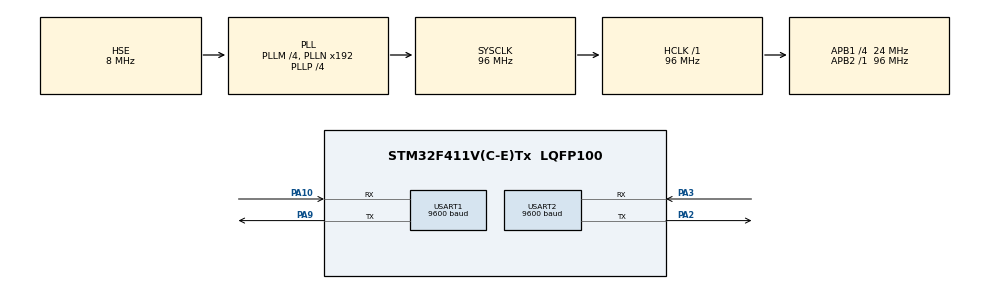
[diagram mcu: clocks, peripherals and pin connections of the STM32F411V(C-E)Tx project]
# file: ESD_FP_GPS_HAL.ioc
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Mcu.Family=STM32F4
Mcu.Name=STM32F411V(C-E)Tx
Mcu.Package=LQFP100
NVIC.PriorityGroup=NVIC_PRIORITYGROUP_0
NVIC.USART1_IRQn=true\:0\:0\:false\:false\:true\:true\:true\:true
PA10.Mode=Asynchronous
PA10.Signal=USART1_RX
PA13.Mode=Serial_Wire
PA13.Signal=SYS_JTMS-SWDIO
PA14.Mode=Serial_Wire
PA14.Signal=SYS_JTCK-SWCLK
PA2.Mode=Asynchronous
PA2.Signal=USART2_TX
PA3.Mode=Asynchronous
PA3.Signal=USART2_RX
PA9.Mode=Asynchronous
PA9.Signal=USART1_TX
PC14-OSC32_IN.Mode=LSE-External-Oscillator
PC14-OSC32_IN.Signal=RCC_OSC32_IN
PC15-OSC32_OUT.Mode=LSE-External-Oscillator
PC15-OSC32_OUT.Signal=RCC_OSC32_OUT
PH0\ -\ OSC_IN.Mode=HSE-External-Oscillator
PH0\ -\ OSC_IN.Signal=RCC_OSC_IN
PH1\ -\ OSC_OUT.Mode=HSE-External-Oscillator
PH1\ -\ OSC_OUT.Signal=RCC_OSC_OUT
ProjectManager.HeapSize=0x200
ProjectManager.StackSize=0x400
ProjectManager.TargetToolchain=STM32CubeIDE
RCC.48MHZClocksFreq_Value=48000000
RCC.AHBFreq_Value=96000000
RCC.APB1CLKDivider=RCC_HCLK_DIV4
RCC.APB1Freq_Value=24000000
RCC.APB1TimFreq_Value=48000000
RCC.APB2Freq_Value=96000000
RCC.APB2TimFreq_Value=96000000
RCC.CortexFreq_Value=96000000
RCC.HCLKFreq_Value=96000000
RCC.HSE_VALUE=8000000
RCC.HSI_VALUE=16000000
RCC.PLLI2SM=5
RCC.PLLI2SN=200
RCC.PLLM=4
RCC.PLLP=RCC_PLLP_DIV4
RCC.PLLQ=8
RCC.PLLSourceVirtual=RCC_PLLSOURCE_HSE
RCC.SYSCLKFreq_VALUE=96000000
RCC.SYSCLKSource=RCC_SYSCLKSOURCE_PLLCLK
RCC.VCOOutputFreq_Value=384000000
USART1.BaudRate=9600
USART1.VirtualMode=VM_ASYNC
USART2.BaudRate=9600
USART2.VirtualMode=VM_ASYNC
board=STM32F411E-DISCO

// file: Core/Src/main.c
/* USER CODE BEGIN Header */
/**
  ******************************************************************************
  * @file           : main.c
  * @brief          : Main program body
  ******************************************************************************
  * @attention
  *
  * Copyright (c) 2024 STMicroelectronics.
  * All rights reserved.
  *
  * This software is licensed under terms that can be found in the LICENSE file
  * in the root directory of this software component.
  * If no LICENSE file comes with this software, it is provided AS-IS.
  *
  ******************************************************************************
  */
/* USER CODE END Header */
#include "main.h"

/* USER CODE BEGIN Includes */
#include "uartRingBuffer.h"
#include "NMEA.h"
#include <stdio.h>
#include <string.h>

/* USER CODE END Includes */

UART_HandleTypeDef huart1;
UART_HandleTypeDef huart2;

void SystemClock_Config(void);
static void MX_GPIO_Init(void);
static void MX_USART1_UART_Init(void);
static void MX_USART2_UART_Init(void);

/* USER CODE BEGIN 0 */
char GGA[100];
char RMC[100];

GPSSTRUCT gpsData;

int flagGGA = 0, flagRMC = 0;
char lcdBuffer [50];

int VCCTimeout = 5000; // GGA or RMC will not be received if the VCC is not sufficient

/* USER CODE END 0 */

int main(void)
{

  /* MCU Configuration--------------------------------------------------------*/

  /* Reset of all peripherals, Initializes the Flash interface and the Systick. */
  HAL_Init();

  /* Configure the system clock */
  SystemClock_Config();

  /* Initialize all configured peripherals */
  MX_GPIO_Init();
  MX_USART1_UART_Init();
  MX_USART2_UART_Init();
  /* USER CODE BEGIN 2 */
  Ringbuf_init();
  HAL_Delay (500);

  /* USER CODE END 2 */

  /* Infinite loop */
  while (1)
  {
	  if (Wait_for("GGA") == 1)
	 	  {
	 		  VCCTimeout = 5000;  // Reset the VCC Timeout indicating the GGA is being received

	 		  Copy_upto("*", GGA);
	 		  if (decodeGGA(GGA, &gpsData.ggastruct) == 0) flagGGA = 2;  // 2 indicates the data is valid
	 		  else flagGGA = 1;  // 1 indicates the data is invalid
	 	  }

	 	  if (Wait_for("RMC") == 1)
	 	  {

	 		  VCCTimeout = 5000;  // Reset the VCC Timeout indicating the RMC is being received

	 		  Copy_upto("*", RMC);
	 		  if (decodeRMC(RMC, &gpsData.rmcstruct) == 0) flagRMC = 2;  // 2 indicates the data is valid
	 		  else flagRMC = 1;  // 1 indicates the data is invalid
	 	  }

	 	  if ((flagGGA == 2) | (flagRMC == 2))
	 	  {
	 		  //lcd_put_cur(0, 0);
	 		  //sprintf (lcdBuffer, "%02d:%02d:%02d, %02d%02d%02d", gpsData.ggastruct.tim.hour, \
	 			//	  gpsData.ggastruct.tim.min, gpsData.ggastruct.tim.sec, gpsData.rmcstruct.date.Day, \
	 				//  gpsData.rmcstruct.date.Mon, gpsData.rmcstruct.date.Yr);
	 		  //HAL_UART_Transmit(&huart2, lcdBuffer, sizeof(lcdBuffer), 100);
	 		  //lcd_send_string(lcdBuffer);
	 		  memset(lcdBuffer, '\0', 50);
	 		  //lcd_put_cur(1, 0);
	 		  sprintf (lcdBuffer, "%.2f%c, %.2f%c  ", gpsData.ggastruct.lcation.latitude, gpsData.ggastruct.lcation.NS,\
	 				  gpsData.ggastruct.lcation.longitude, gpsData.ggastruct.lcation.EW);
	 		  HAL_UART_Transmit(&huart2, lcdBuffer, sizeof(lcdBuffer), 100);
//	 		  lcd_send_string(lcdBuffer);
	 	  }

	 	  else if ((flagGGA == 1) | (flagRMC == 1))
	 	  {
	 		  // Instead of clearing the display, it's better if we print spaces.
	 		  // This will avoid the "refreshing" part
	 		  //lcd_put_cur(0, 0);
	 		  char message[] = "   NO FIX YET   ";
	 		  HAL_UART_Transmit(&huart2, message, sizeof(message), 100);
//	 		  lcd_put_cur(1, 0);
//	 		  lcd_send_string("   Please wait  ");
	 	  }

	 	  if (VCCTimeout <= 0)
	 	  {
	 		  VCCTimeout = 5000;  // Reset the timeout

	 		  //reset flags
	 		  flagGGA =flagRMC =0;

	 		  // You are here means the VCC is less, or maybe there is some connection issue
	 		  // Check the VCC, also you can try connecting to the external 5V

//	 		  lcd_put_cur(0, 0);
	 		 char message[] = "    VCC Issue   ";
	 		 HAL_UART_Transmit(&huart2, message, sizeof(message), 100);
//	 		  lcd_send_string("    VCC Issue   ");
//	 		  lcd_put_cur(1, 0);
//	 		  lcd_send_string("Check Connection");
	 	  }

  }
}

void SystemClock_Config(void)
{
  RCC_OscInitTypeDef RCC_OscInitStruct = {0};
  RCC_ClkInitTypeDef RCC_ClkInitStruct = {0};

  /** Configure the main internal regulator output voltage
  */
  __HAL_RCC_PWR_CLK_ENABLE();
  __HAL_PWR_VOLTAGESCALING_CONFIG(PWR_REGULATOR_VOLTAGE_SCALE1);

  /** Initializes the RCC Oscillators according to the specified parameters
  * in the RCC_OscInitTypeDef structure.
  */
  RCC_OscInitStruct.OscillatorType = RCC_OSCILLATORTYPE_HSE;
  RCC_OscInitStruct.HSEState = RCC_HSE_ON;
  RCC_OscInitStruct.PLL.PLLState = RCC_PLL_ON;
  RCC_OscInitStruct.PLL.PLLSource = RCC_PLLSOURCE_HSE;
  RCC_OscInitStruct.PLL.PLLM = 4;
  RCC_OscInitStruct.PLL.PLLN = 192;
  RCC_OscInitStruct.PLL.PLLP = RCC_PLLP_DIV4;
  RCC_OscInitStruct.PLL.PLLQ = 8;
  if (HAL_RCC_OscConfig(&RCC_OscInitStruct) != HAL_OK)
  {
    Error_Handler();
  }

  /** Initializes the CPU, AHB and APB buses clocks
  */
  RCC_ClkInitStruct.ClockType = RCC_CLOCKTYPE_HCLK|RCC_CLOCKTYPE_SYSCLK
                              |RCC_CLOCKTYPE_PCLK1|RCC_CLOCKTYPE_PCLK2;
  RCC_ClkInitStruct.SYSCLKSource = RCC_SYSCLKSOURCE_PLLCLK;
  RCC_ClkInitStruct.AHBCLKDivider = RCC_SYSCLK_DIV1;
  RCC_ClkInitStruct.APB1CLKDivider = RCC_HCLK_DIV4;
  RCC_ClkInitStruct.APB2CLKDivider = RCC_HCLK_DIV1;

  if (HAL_RCC_ClockConfig(&RCC_ClkInitStruct, FLASH_LATENCY_3) != HAL_OK)
  {
    Error_Handler();
  }
}

static void MX_USART1_UART_Init(void)
{

  huart1.Instance = USART1;
  huart1.Init.BaudRate = 9600;
  huart1.Init.WordLength = UART_WORDLENGTH_8B;
  huart1.Init.StopBits = UART_STOPBITS_1;
  huart1.Init.Parity = UART_PARITY_NONE;
  huart1.Init.Mode = UART_MODE_TX_RX;
  huart1.Init.HwFlowCtl = UART_HWCONTROL_NONE;
  huart1.Init.OverSampling = UART_OVERSAMPLING_16;
  if (HAL_UART_Init(&huart1) != HAL_OK)
  {
    Error_Handler();
  }

}

static void MX_USART2_UART_Init(void)
{

  huart2.Instance = USART2;
  huart2.Init.BaudRate = 9600;
  huart2.Init.WordLength = UART_WORDLENGTH_8B;
  huart2.Init.StopBits = UART_STOPBITS_1;
  huart2.Init.Parity = UART_PARITY_NONE;
  huart2.Init.Mode = UART_MODE_TX_RX;
  huart2.Init.HwFlowCtl = UART_HWCONTROL_NONE;
  huart2.Init.OverSampling = UART_OVERSAMPLING_16;
  if (HAL_UART_Init(&huart2) != HAL_OK)
  {
    Error_Handler();
  }

}

static void MX_GPIO_Init(void)
{

  /* GPIO Ports Clock Enable */
  __HAL_RCC_GPIOC_CLK_ENABLE();
  __HAL_RCC_GPIOH_CLK_ENABLE();
  __HAL_RCC_GPIOA_CLK_ENABLE();

}

void Error_Handler(void)
{
  __disable_irq();
  while (1)
  {
  }
}
